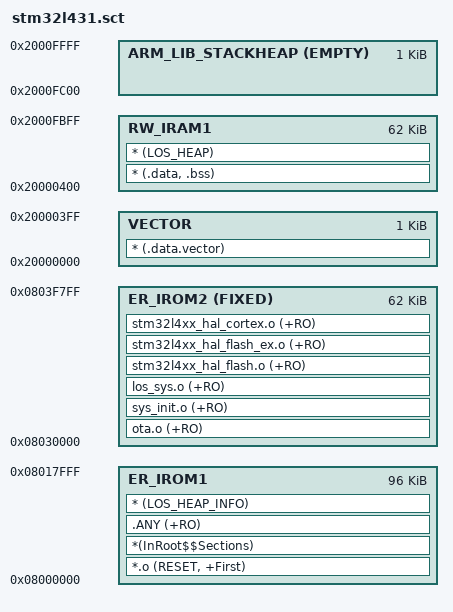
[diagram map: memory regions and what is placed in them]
; *************************************************************
; *** Scatter-Loading Description File generated by uVision ***
; *************************************************************

LR_IROM1 0x08000000 0x00040000  {    ; load region size_region
    ER_IROM1 0x08000000 0x00018000  {    ; load address = execution address
        *.o (RESET, +First)
        *(InRoot$$Sections)
        .ANY (+RO)
        * (LOS_HEAP_INFO)
    }
	;ER_IROM3 0x08018000 0x00018000  {	;ota area
	;}
	ER_IROM2 0x08030000 FIXED 0x0000f800  {	;ota code
		ota.o (+RO)
		;below for flash related(use after normal area erased)
		sys_init.o (+RO)
		los_sys.o (+RO)
		stm32l4xx_hal_flash.o (+RO)
		stm32l4xx_hal_flash_ex.o (+RO)
		;below for sw reset(use after normal area erased)
		stm32l4xx_hal_cortex.o (+RO)
	}
	;ER_IROM4 0x0803f800 0x00000800  {	;data store
	;}
    VECTOR 0x20000000 0x400  {    ; Vector
        * (.data.vector)
    }
    RW_IRAM1 0x20000400 0x0000F800  {    ; RW data
        ;.ANY (+RW +ZI)
        * (.data, .bss)
        * (LOS_HEAP)
    }
    ARM_LIB_STACKHEAP 0x2000FC00 EMPTY 0x400  {    ;LiteOS MSP
    }
}
